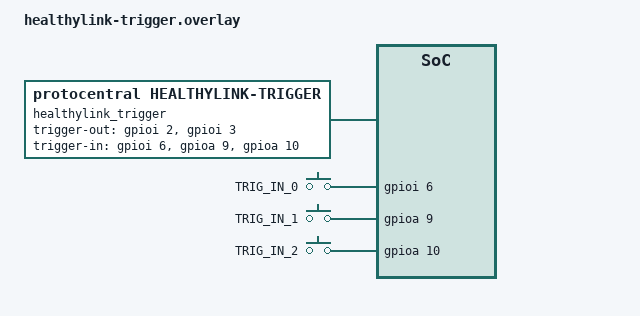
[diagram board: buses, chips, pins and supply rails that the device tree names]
/*
 * HealthyLink Trigger I/O Module Overlay
 * Copyright (c) 2025 ProtoCentral
 * SPDX-License-Identifier: MIT
 *
 * Lab trigger inputs and outputs with precise timing for
 * experiment synchronization and event marking.
 * Module ID: 0x0003
 *
 * Hardware Connections:
 *   GPIO Outputs: PI2 (TRIG_OUT_0), PI3 (TRIG_OUT_1)
 *   GPIO Inputs:  PI6 (TRIG_IN_0), PA9 (TRIG_IN_1), PA10 (TRIG_IN_2)
 *
 * Features:
 *   - Microsecond-precision timestamping using DWT cycle counter
 *   - Interrupt-driven input detection
 *   - Direct GPIO control for minimal output latency
 *   - Configurable pull-up/pull-down on inputs
 *
 * Typical Use Cases:
 *   - Stimulus presentation synchronization
 *   - Event marking in biosignal recordings
 *   - External device synchronization
 *   - TTL trigger for oscilloscopes/amplifiers
 *
 * Usage:
 *   west build -b healthypi6_v2/stm32h757xx/m7 app_m7 \
 *       -DEXTRA_DTC_OVERLAY_FILE="boards/protocentral/healthypi6_v2/healthylink-trigger.overlay"
 */

/* Include base HealthyLink definitions */
#include "healthylink.dtsi"

/ {
	/* HealthyLink Trigger module binding */
	healthylink_trigger: healthylink-trigger {
		compatible = "protocentral,healthylink-trigger";
		status = "okay";

		/* Module identification */
		module-id = <0x0003>;

		/* Trigger outputs - directly controlled GPIOs
		 * Active high: set GPIO high to assert trigger
		 * Module hardware may include level shifters for 5V TTL output
		 */
		trigger-out-gpios = <&gpioi 2 GPIO_ACTIVE_HIGH>,  /* PI2 - TRIG_OUT_0 */
		                    <&gpioi 3 GPIO_ACTIVE_HIGH>;  /* PI3 - TRIG_OUT_1 */

		/* Trigger inputs - interrupt capable GPIOs
		 * Pull-down enabled: triggers on rising edge (logic high)
		 * Module hardware should include Schmitt trigger for noise immunity
		 *
		 * Input voltage: 3.3V logic (5V tolerant on PI pins only)
		 * Minimum pulse width: ~100ns for reliable detection
		 */
		trigger-in-gpios = <&gpioi 6 (GPIO_ACTIVE_HIGH | GPIO_PULL_DOWN)>,   /* PI6 - TRIG_IN_0 */
		                   <&gpioa 9 (GPIO_ACTIVE_HIGH | GPIO_PULL_DOWN)>,   /* PA9 - TRIG_IN_1 */
		                   <&gpioa 10 (GPIO_ACTIVE_HIGH | GPIO_PULL_DOWN)>;  /* PA10 - TRIG_IN_2 */

		/* Timestamp resolution in nanoseconds
		 * STM32H7 M7 core at 400 MHz = 2.5ns cycle time
		 * Using DWT CYCCNT for precise timestamping
		 */
		timestamp-resolution-ns = <10>;  /* 10ns effective resolution */

		/* Input debounce time in microseconds
		 * Set to 0 for no debouncing (fastest response)
		 * Typical values: 0-1000 us depending on signal quality
		 */
		debounce-us = <0>;

		/* Enable edge detection on inputs */
		detect-rising-edge;
		detect-falling-edge;
	};

	/* GPIO key bindings for interrupt-driven trigger inputs
	 * This allows using Zephyr's input subsystem for trigger events
	 */
	trigger_inputs: trigger-inputs {
		compatible = "gpio-keys";
		status = "okay";

		trigger_in_0: trigger_in_0 {
			gpios = <&gpioi 6 (GPIO_ACTIVE_HIGH | GPIO_PULL_DOWN)>;
			label = "TRIG_IN_0";
			zephyr,code = <0>;  /* Custom event code */
		};

		trigger_in_1: trigger_in_1 {
			gpios = <&gpioa 9 (GPIO_ACTIVE_HIGH | GPIO_PULL_DOWN)>;
			label = "TRIG_IN_1";
			zephyr,code = <1>;
		};

		trigger_in_2: trigger_in_2 {
			gpios = <&gpioa 10 (GPIO_ACTIVE_HIGH | GPIO_PULL_DOWN)>;
			label = "TRIG_IN_2";
			zephyr,code = <2>;
		};
	};

	/* Update chosen node for trigger module */
	chosen {
		healthylink-module = &healthylink_trigger;
	};

	/* Aliases for quick access */
	aliases {
		trigger-out0 = &gpioi;  /* Pin 2 */
		trigger-out1 = &gpioi;  /* Pin 3 */
		trigger-in0 = &trigger_in_0;
		trigger-in1 = &trigger_in_1;
		trigger-in2 = &trigger_in_2;
	};
};
